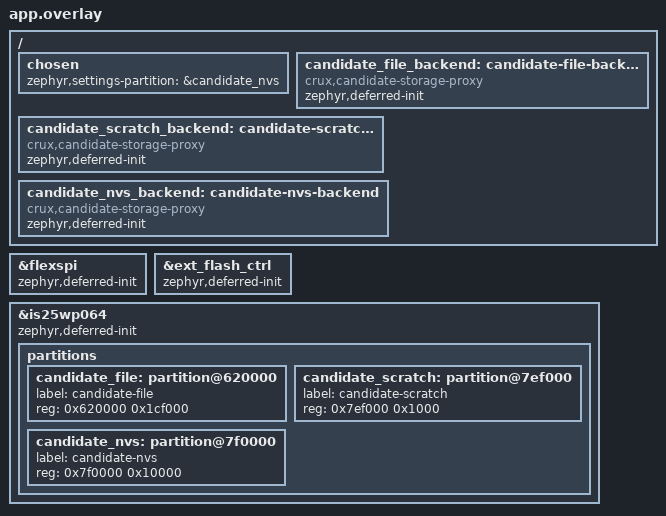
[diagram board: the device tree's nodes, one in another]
/* SPDX-License-Identifier: Apache-2.0 */
/* Experimental owners only. No production layout or physical write approval. */
/ { chosen { zephyr,settings-partition = &candidate_nvs; }; };
&flexspi { zephyr,deferred-init; };
&ext_flash_ctrl { zephyr,deferred-init; };
&is25wp064 {
    zephyr,deferred-init;
    partitions {
        /* Remove the broad native storage area, including its fallback label. */
        /delete-node/ partition@620000;

        candidate_file: partition@620000 {
            label = "candidate-file";
            reg = <0x620000 0x1cf000>;
        };

        candidate_scratch: partition@7ef000 {
            label = "candidate-scratch";
            reg = <0x7ef000 0x1000>;
        };

        candidate_nvs: partition@7f0000 {
            label = "candidate-nvs";
            reg = <0x7f0000 0x10000>;
        };
    };
};

/ {
    candidate_file_backend: candidate-file-backend {
        compatible = "crux,candidate-storage-proxy";
        zephyr,deferred-init;
    };
    candidate_scratch_backend: candidate-scratch-backend {
        compatible = "crux,candidate-storage-proxy";
        zephyr,deferred-init;
    };
    candidate_nvs_backend: candidate-nvs-backend {
        compatible = "crux,candidate-storage-proxy";
        zephyr,deferred-init;
    };
};
